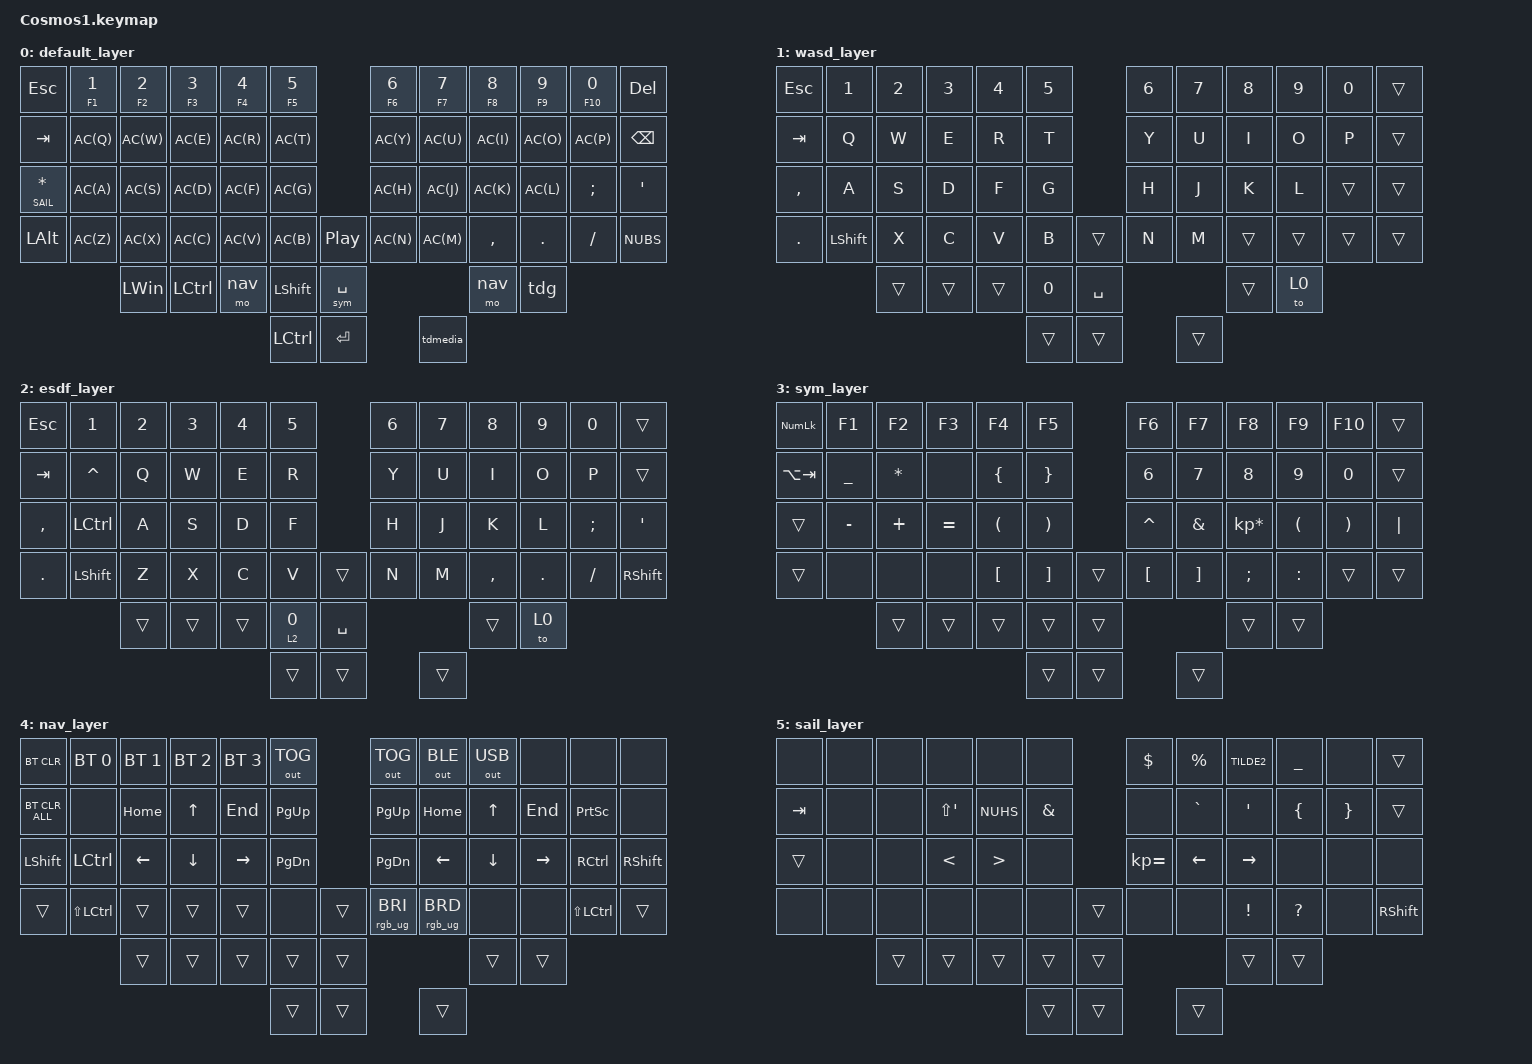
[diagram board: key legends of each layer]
/*
 * Copyright (c) 2020 The ZMK Contributors
 *
 * SPDX-License-Identifier: MIT
 */

#include <behaviors.dtsi>
#include <dt-bindings/zmk/keys.h>
#include <dt-bindings/zmk/bt.h>
#include <dt-bindings/zmk/rgb.h>
#include <dt-bindings/zmk/outputs.h>  
 
// #define ZMK_POINTING_DEFAULT_MOVE_VAL 600  // default: 600
#define ZMK_POINTING_DEFAULT_SCRL_VAL 140    // default: 10
#include <dt-bindings/zmk/pointing.h>

#define wasd 1
#define esdf 2
#define sym 3
#define nav 4
#define SAIL 5

#define MEH(key) LS(LC(LA(key)))

/ {
    left_encoder: encoder_left {
        compatible = "alps,ec11";
        label = "LEFT_ENCODER";
        a-gpios = <&pro_micro 21 (GPIO_ACTIVE_HIGH | GPIO_PULL_UP)>;
        b-gpios = <&pro_micro 20 (GPIO_ACTIVE_HIGH | GPIO_PULL_UP)>;
        steps = <80>;
    };

    right_encoder: encoder_right {
        compatible = "alps,ec11";
        label = "RIGHT_ENCODER";
        a-gpios = <&pro_micro 20 (GPIO_ACTIVE_HIGH | GPIO_PULL_UP)>;
        b-gpios = <&pro_micro 21 (GPIO_ACTIVE_HIGH | GPIO_PULL_UP)>;
        steps = <80>;
    };

    sensors {
        compatible = "zmk,keymap-sensors";
        sensors = <&left_encoder &right_encoder>;
        triggers-per-rotation = <20>;
    };
};

	
/ {
    macros {
		ZMK_MACRO(equiv,
			wait-ms = <0>;
			tap-ms = <0>;
			bindings
				= <&macro_tap     &kp RALT &kp U &kp KP_N2 &kp KP_N2 &kp KP_N6 &kp KP_N1 &kp RET>;
		)
	};
};

/ {
    macros {
		ZMK_MACRO(equiv2,
			wait-ms = <0>;
			tap-ms = <0>;
			bindings
				= <&macro_tap     &kp KP_N2 &kp KP_N2 &kp KP_N6 &kp KP_N1 &kp LALT &kp X>;
		)
	};
};


#define AC(keycode) &ac LC(keycode) keycode     // Autoctrl Macro

/ {
    behaviors {
        ac: auto_ctrl {
            compatible = "zmk,behavior-hold-tap";
            label = "AUTO_CTRL";
            #binding-cells = <2>;
            tapping_term_ms = <200>;
            quick_tap_ms = <125>;
			global-quick-tap;
            flavor = "tap-preferred";
            bindings = <&kp>, <&kp>;
        };
    };
};
	
/ {
    behaviors {
        tdmedia: tap_dance_media {
            compatible = "zmk,behavior-tap-dance";
            label = "TAP_DANCE_MEDIA";
            #binding-cells = <0>;
            tapping-term-ms = <300>;
            bindings =
				<&ht C_MUTE C_PLAY_PAUSE>, <&kp C_NEXT>, <&kp C_PREVIOUS>;
        };
    };
};

/ {
    behaviors {
        ht: hold_tap {
            compatible = "zmk,behavior-hold-tap";
            label = "HOLD_TAP";
            #binding-cells = <2>;
            tapping_term_ms = <200>;
            quick_tap_ms = <125>;
            flavor = "tap-preferred";
            bindings = <&kp>, <&kp>;
        };
    };
};

/ {
    behaviors {
        hltl: hold_layer_tap_layer {
            compatible = "zmk,behavior-hold-tap";
            label = "HOLD_LAYER_TAP_LAYER";
            #binding-cells = <2>;
            tapping_term_ms = <200>;
            quick_tap_ms = <125>;
			global-quick-tap;
            flavor = "tap-preferred";
            bindings = <&mo>, <&tog>;
        };
    };
};

/ {
    behaviors {
        tdg: tap_dance_gaming_layers {
            compatible = "zmk,behavior-tap-dance";
            label = "TAP_DANCE_GAMING_LAYERS";
            #binding-cells = <0>;
            tapping-term-ms = <200>;
            bindings = <&to esdf>, <&to wasd>;
        };
    };
};

/ {
    behaviors {
        scroll_up_down: scroll_up_down {
            compatible = "zmk,behavior-sensor-rotate";
            #sensor-binding-cells = <0>;
            bindings = <&msc SCRL_DOWN>, <&msc SCRL_UP>;
            tap-ms = <250>;
        };
    };
};


/ {
    keymap {
        compatible = "zmk,keymap";

        default_layer {
// ------------------------------------------------------------------------------------------------------------
// |  ESC  |  1  |  2  |  3   |  4   |  5   |                   |  6   |  7    |  8    |  9   |   0   |  DEL  |
// |  TAB  |  Q  |  W  |  E   |  R   |  T   |                   |  Y   |  U    |  I    |  O   |   P   | BKSPC |
// |  SAIL |  A  |  S  |  D   |  F   |  G   |                   |  H   |  J    |  K    |  L   |   ;   |   '   |
// | SHIFT |  Z  |  X  |  C   |  V   |  B   |  MUTE  |  |  MIC  |  N   |  M    |  ,    |  .   |   /   | SHIFT |
//               | GUI | ALT  | CTRL | LOWER|  SPACE |  | ENTER | RAISE| CTRL  | ALT   | GUI  |
            bindings = <
&kp ESC       &ac F1 N1 &ac F2 N2 &ac F3 N3  &ac F4 N4 &ac F5 N5                            &ac F6 N6    &ac F7 N7 &ac F8 N8  &ac F9 N9 &ac F10 N0 &kp DEL 
&kp TAB       AC(Q)     AC(W)     AC(E)     AC(R)      AC(T)                                AC(Y)        AC(U)     AC(I)      AC(O)     AC(P)      &kp BSPC
&lt SAIL STAR AC(A)     AC(S)     AC(D)     AC(F)      AC(G)                                AC(H)        AC(J)     AC(K)      AC(L)     &kp SEMI   &kp SQT
&kp LALT      AC(Z)     AC(X)     AC(C)     AC(V)      AC(B)   &kp C_PLAY_PAUSE             AC(N)        AC(M)     &kp COMMA  &kp DOT   &kp FSLH   &kp NUBS
                        &kp LWIN  &kp LCTRL &mo nav    &kp LSHFT  &lt sym SPACE                                    &mo nav    &tdg
                                                       &kp LCTRL  &kp RET                                     &tdmedia
            >;

            sensor-bindings = <&inc_dec_kp C_VOL_UP C_VOL_DN &scroll_up_down>;
        };
		
		
		wasd_layer {
			bindings = <
&kp ESC   &kp N1    &kp N2   &kp N3    &kp N4    &kp N5                      &kp N6  &kp N7    &kp N8    &kp N9    &kp N0   &trans
&kp TAB   &kp Q     &kp W    &kp E     &kp R     &kp T                       &kp Y   &kp U     &kp I     &kp O     &kp P    &trans
&kp COMMA &kp A     &kp S    &kp D     &kp F     &kp G                       &kp H   &kp J     &kp K     &kp L     &trans   &trans
&kp DOT   &kp LSHFT &kp X    &kp C     &kp V     &kp B    &trans             &kp N   &kp M     &trans    &trans    &trans   &trans
                    &trans   &trans    &trans    &kp N0   &kp SPACE                            &trans    &to 0
                                                 &trans   &trans                          &trans
			>;

            sensor-bindings = <&inc_dec_kp C_VOL_UP C_VOL_DN &scroll_up_down>;
		};
		
		
		esdf_layer {
			bindings = <
&kp ESC   &kp N1    &kp N2   &kp N3   &kp N4    &kp N5                          &kp N6  &kp N7    &kp N8    &kp N9    &kp N0   &trans
&kp TAB   &kp CARET &kp Q    &kp W    &kp E     &kp R                           &kp Y   &kp U     &kp I     &kp O     &kp P    &trans
&kp COMMA &kp LCTRL &kp A    &kp S    &kp D     &kp F                           &kp H   &kp J     &kp K     &kp L     &kp SEMI &kp SQT
&kp DOT   &kp LSHFT &kp Z    &kp X    &kp C     &kp V     &trans                &kp N   &kp M     &kp COMMA &kp DOT   &kp FSLH &kp RSHFT
                    &trans   &trans   &trans    &lt 2 N0  &kp SPACE                               &trans    &to 0
                                                &trans    &trans                             &trans

			>;

            sensor-bindings = <&inc_dec_kp C_VOL_UP C_VOL_DN &scroll_up_down>;
		};


        sym_layer {
// ------------------------------------------------------------------------------------------------------------
// |  NUM  |  F1 |  F2 |  F3  |  F4  |  F5  |                   |  F6  |  F7   |  F8   |  F9  |  F10  |  F11  |
// | `     |  _  |  *  |      |  {   |   }  |                   |   6  |   7   |   8   |   9  |    0  |  F12  |
// |       |  -  |  +  |  =   |  (   |  )   |                   |  ^   |  &    |  *    |  (   |   )   |   |   |
// |       |     |     |      |  [   |  ]   |        |  |       |  [   |  ]    |  ;    |  :   |   \   |       |
//               |     |      |      |      |        |  |       |      |       |       |      |
            bindings = <
&kp KP_NUM  &kp F1    &kp F2    &kp F3      &kp F4    &kp F5                     &kp F6    &kp F7   &kp F8          &kp F9    &kp F10   &trans
&kp LA(TAB) &kp UNDER &kp STAR  &none       &kp LBRC  &kp RBRC                   &kp N6    &kp N7   &kp N8          &kp N9    &kp N0    &trans
&trans      &kp MINUS &kp PLUS  &kp EQUAL   &kp LPAR  &kp RPAR                   &kp CARET &kp AMPS &kp KP_MULTIPLY &kp LPAR  &kp RPAR  &kp PIPE
&trans      &none     &none     &none       &kp LBKT  &kp RBKT   &trans          &kp LBKT  &kp RBKT &kp SEMI        &kp COLON &trans    &trans
                      &trans    &trans      &trans    &trans     &trans                             &trans          &trans
                                                      &trans     &trans                        &trans

            >;

            sensor-bindings = <&inc_dec_kp C_VOL_UP C_VOL_DN &scroll_up_down>;
        };



        nav_layer {
// ------------------------------------------------------------------------------------------------------------
// |BTCLR| BT1  | BT2  |  BT3  |  BT4  |  BT5 |                |      |      |       |      |       |       |
// |     |      | HOME |   ^   |  END  | PGUP |                | PGUP | HOME |   ^   |  END |       |       |
// |SHIFT| SHIFT|   <- |   v   |  ->   | PGDN |                | PGDN |   <- |   v   |  ->  | SHFIT | SHIFT |
// |     | CTRL |      |       |       |      |      |  |      |      |      |       |      | CTRL  |       |
//              |      |       |       |      |      |  |      |      |      |       |      |
            bindings = <
&bt BT_CLR &bt BT_SEL 0  &bt BT_SEL 1 &bt BT_SEL 2 &bt BT_SEL 3 &out OUT_TOG                &out OUT_TOG    &out OUT_BLE    &out OUT_USB    &none     &none         &none
&bt BT_CLR_ALL &none     &kp HOME     &kp UP       &kp END      &kp PG_UP                   &kp PG_UP       &kp HOME        &kp UP          &kp END   &kp PSCRN     &none
&kp LSHIFT &kp LCTRL     &kp LEFT     &kp DOWN     &kp RIGHT    &kp PG_DN                   &kp PG_DN       &kp LEFT        &kp DOWN        &kp RIGHT &kp RCTRL     &kp RSHFT
&trans     &kp LS(LCTRL) &trans       &trans       &trans       &none      &trans           &rgb_ug RGB_BRI &rgb_ug RGB_BRD &none           &none     &kp LS(LCTRL) &trans
                         &trans       &trans       &trans       &trans     &trans                                           &trans          &trans
                                                                &trans     &trans                                      &trans
            >;

            sensor-bindings = <&inc_dec_kp C_VOL_UP C_VOL_DN &scroll_up_down>;
        };
		
		
		
		sail_layer {
// ------------------------------------------------------------------------------------------------------------
// |     |  ≡   |   ∩  |   ∪   |   ⊂   |   $  |                |   $   |   %   |   ~   |   _   |       |       |
// |     |      |      |   @   |   #   |   &  |                |       |   `   |   '   |   {   |   }   |  BKSP |
// |  ⊗  |  ≤   |   ≥  |   <   |   >   |   ≠  |                |   =   |   ←   |   →   |   ↔   |   ↓   |       |
// |SHIFT|   α  |   β  |   ε   |   λ   |   π  |      |  |      |   ∀   |   ∃   |   !   |   ?   |   ∂   | SHIFT |
//              |      |       |       |      |      |  |      |       |       |       |       |
            bindings = <
&none      &none        &none        &none        &none        &none                    &kp DLLR     &kp PRCNT &kp TILDE2 &kp UNDER &none    &trans 
&kp TAB    &none        &none        &kp LS(SQT)  &kp NUHS     &kp AMPS                 &none        &kp GRAVE &kp SQT    &kp LBRC  &kp RBRC &trans
&trans     &none        &none        &kp LT       &kp GT       &none                    &kp KP_EQUAL &kp LEFT  &kp RIGHT  &none     &none    &none    
&none      &none        &none        &none        &none        &none    &trans          &none        &none     &kp EXCL   &kp QMARK &none    &kp RSHFT 
                        &trans       &trans       &trans       &trans   &trans                                 &trans     &trans 
                                                  &trans   &trans                                         &trans

            >;

            sensor-bindings = <&inc_dec_kp C_VOL_UP C_VOL_DN &scroll_up_down>;
        };
	};
};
